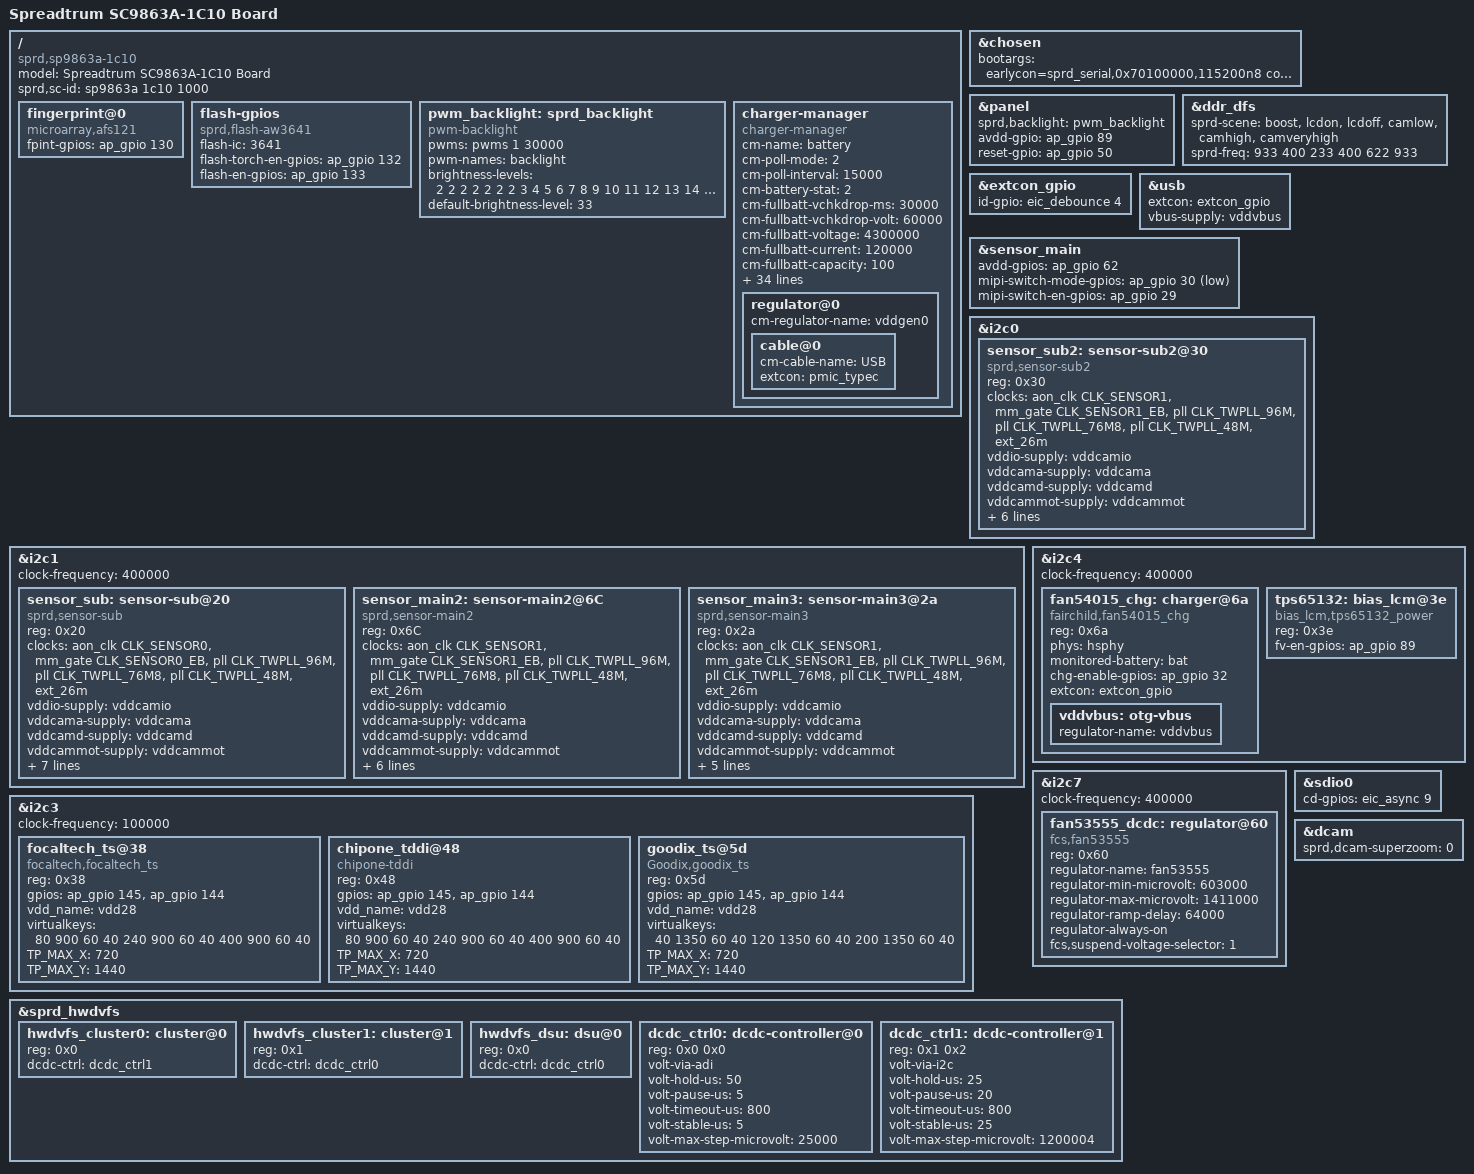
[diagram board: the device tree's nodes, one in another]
/dts-v1/;
/plugin/;

#include <dt-bindings/input/input.h>
#include <dt-bindings/gpio/gpio.h>
#include <dt-bindings/clock/sprd,sc9863a-clk.h>

/ {
	model = "Spreadtrum SC9863A-1C10 Board";
	compatible = "sprd,sp9863a-1c10", "sprd,sc9863a";
	sprd,sc-id = "sp9863a 1c10 1000";

	fragment {
		target-path = "/";
		__overlay__ {
			fingerprint@0 {
				compatible = "microarray,afs121";
				fpint-gpios = <&ap_gpio 130 0>;
			};

			flash-gpios {
				compatible = "sprd,flash-aw3641";
				flash-ic = <3641>;
				flash-torch-en-gpios = <&ap_gpio 132 0>;
				flash-en-gpios = <&ap_gpio 133 0>;
			};

			pwm_backlight: sprd_backlight {
				compatible = "pwm-backlight";
				pwms = <&pwms 1 30000>;
				pwm-names = "backlight";
				brightness-levels = <
								  2   2   2   2
					  2   2   2   3   4   5   6   7   8   9
					 10  11  12  13  14  15  16  17  18  19
					 20  21  22  23  24  25  26  27  28  29
					 30  31  32  33  34  35  36  37  38  39
					 40  41  42  43  44  45  46  47  48  49
					 50  51  52  53  54  55  56  57  58  59
					 60  61  62  63  64  65  66  67  68  69
					 70  71  72  73  74  75  76  77  78  79
					 80  81  82  83  84  85  86  87  88  89
					 90  91  92  93  94  95  96  97  98  99
					100 101 102 103 104 105 106 107 108 109
					110 111 112 113 114 115 116 117 118 119
					120 121 122 123 124 125 126 127 128 129
					130 131 132 133 134 135 136 137 138 139
					140 141 142 143 144 145 146 147 148 149
					150 151 152 153 154 155 156 157 158 159
					160 161 162 163 164 165 166 167 168 169
					170 171 172 173 174 175 176 177 178 179
					180 181 182 183 184 185 186 187 188 189
					190 191 192 193 194 195 196 197 198 199
					200 201 202 203 204 205 206 207 208 209
					210 211 212 213 214 215 216 217 218 219
					220 221 222 223 224 225 226 227 228 229
					230 231 232 233 234 235 236 237 238 239
					240 241 242 243 244 245 246 247 248 249
					250 251
				>;
				default-brightness-level = <33>;
			};

			charger-manager {
				compatible = "charger-manager";
				cm-name = "battery";
				cm-poll-mode = <2>;
				cm-poll-interval = <15000>;
				cm-battery-stat = <2>;

				cm-fullbatt-vchkdrop-ms = <30000>;
				cm-fullbatt-vchkdrop-volt = <60000>;
				cm-fullbatt-voltage = <4300000>;
				cm-fullbatt-current = <120000>;
				cm-fullbatt-capacity = <100>;

				cm-num-chargers = <1>;
				cm-chargers = "fan54015_charger";
				cm-fuel-gauge = "sc27xx-fgu";

				/* in deci centigrade */
				cm-battery-cold = <200>;
				cm-battery-cold-in-minus;
				cm-battery-hot = <800>;
				cm-battery-temp-diff = <100>;

				/* Allow charging for 6hr */
				cm-charging-max = <21600000>;
				/* recovery charging after stop charging 3hr */
				cm-discharging-max = <10800000>;

				/* the interval to feed charger watchdog */
				cm-wdt-interval = <60>;

				/* drop voltage in microVolts to allow shutdown */
				cm-shutdown-voltage = <3100000>;

				/* when 99% of the time is exceeded, it will be forced to 100% */
				cm-tickle-time-out = <1500>;

				/* how much time to allow capacity change */
				cm-one-cap-time = <30>;

				/* when the safe charging voltage is exceeded, stop charging */
				cm-charge-voltage-max = <6500000>;
				/* drop voltage in microVolts to restart charging */
				cm-charge-voltage-drop = <700000>;
				cm-dcp-jeita-temp-table = <1000 1030 0 4350000>,
					<1150 1180 700000 4350000>,
					<1450 1420 1150000 4350000>,
					<1600 1570 700000 4100000>;
				cm-sdp-jeita-temp-table = <1000 1030 0 4350000>,
					<1150 1180 500000 4350000>,
					<1450 1420 500000 4350000>,
					<1600 1570 500000 4100000>;
				cm-cdp-jeita-temp-table = <1000 1030 0 4350000>,
					<1150 1180 700000 4350000>,
					<1450 1420 1150000 4350000>,
					<1600 1570 700000 4100000>;
				cm-unknown-jeita-temp-table = <1000 1030 0 4350000>,
					<1150 1180 500000 4350000>,
					<1450 1420 500000 4350000>,
					<1600 1570 500000 4100000>;

				monitored-battery = <&bat>;
				cm-capacity-track;

				regulator@0 {
					cm-regulator-name = "vddgen0";
					cable@0 {
						cm-cable-name = "USB";
						extcon = <&pmic_typec>;
					};
				};
			};
		};
	};
};

&chosen {
	bootargs = "earlycon=sprd_serial,0x70100000,115200n8 console=ttyS1,115200n8 loglevel=1 init=/init root=/dev/ram0 rw androidboot.hardware=s9863a1c10 androidboot.dtbo_idx=0 printk.devkmsg=on androidboot.boot_devices=soc/soc:ap-ahb/20600000.sdio";
};

&panel {
	sprd,backlight = <&pwm_backlight>;
	avdd-gpio = <&ap_gpio 89 GPIO_ACTIVE_HIGH>;
	reset-gpio = <&ap_gpio 50 GPIO_ACTIVE_HIGH>;
};

&ddr_dfs {
	sprd-scene = "boost", "lcdon", "lcdoff", "camlow",
			"camhigh", "camveryhigh";
	sprd-freq = <933 400 233 400 622 933>;
};

&extcon_gpio {
	id-gpio = <&eic_debounce 4 GPIO_ACTIVE_HIGH>;
};

&usb {
	extcon = <&extcon_gpio>;
	vbus-supply = <&vddvbus>;
};

&sensor_main {
	avdd-gpios=<&ap_gpio 62 0>;
	mipi-switch-mode-gpios= <&ap_gpio 30 1>;
	mipi-switch-en-gpios= <&ap_gpio 29 0>;
};

&i2c0 {
	sensor_sub2: sensor-sub2@30 {
		compatible = "sprd,sensor-sub2";
		reg = <0x30>;
		clock-names = "clk_src","sensor_eb",
			"clk_96m","clk_76m8",
			"clk_48m","clk_26m";
		clocks = <&aon_clk CLK_SENSOR1>, <&mm_gate CLK_SENSOR1_EB>,
			<&pll CLK_TWPLL_96M>,<&pll CLK_TWPLL_76M8>,
			<&pll CLK_TWPLL_48M>,<&ext_26m>;
		vddio-supply = <&vddcamio>;
		vddcama-supply = <&vddcama>;
		vddcamd-supply = <&vddcamd>;
		vddcammot-supply = <&vddcammot>;
		sprd,phyid = <2>;
		csi = <&csi1>;
		iovdd-gpios=<&ap_gpio 15 0>;
		dvdd-gpios=<&ap_gpio 5 0>;
		reset-gpios = <&ap_gpio 16 0>;
		power-down-gpios = <&ap_gpio 57 0>;
	};
};

&i2c1 {
	status = "okay";
	clock-frequency = <400000>;

	sensor_sub: sensor-sub@20 {
		compatible = "sprd,sensor-sub";
		reg = <0x20>;
		clock-names = "clk_src","sensor_eb",
			"clk_96m","clk_76m8",
			"clk_48m","clk_26m";
		clocks = <&aon_clk CLK_SENSOR0>, <&mm_gate CLK_SENSOR0_EB>,
			<&pll CLK_TWPLL_96M>,<&pll CLK_TWPLL_76M8>,
			<&pll CLK_TWPLL_48M>,<&ext_26m>;
		vddio-supply = <&vddcamio>;
		vddcama-supply = <&vddcama>;
		vddcamd-supply = <&vddcamd>;
		vddcammot-supply = <&vddcammot>;
		sprd,phyid = <1>;
		csi = <&csi0>;
		avdd-gpios=<&ap_gpio 62 0>;
		mipi-switch-mode-gpios= <&ap_gpio 30 0>;
		mipi-switch-en-gpios= <&ap_gpio 29 0>;
		reset-gpios = <&ap_gpio 41 0>;
		power-down-gpios = <&ap_gpio 40 0>;
	};

	sensor_main2: sensor-main2@6C {
		compatible = "sprd,sensor-main2";
		reg = <0x6C>;
		clock-names = "clk_src","sensor_eb",
			"clk_96m","clk_76m8",
			"clk_48m","clk_26m";
		clocks = <&aon_clk CLK_SENSOR1>, <&mm_gate CLK_SENSOR1_EB>,
			<&pll CLK_TWPLL_96M>,<&pll CLK_TWPLL_76M8>,
			<&pll CLK_TWPLL_48M>,<&ext_26m>;
		vddio-supply = <&vddcamio>;
		vddcama-supply = <&vddcama>;
		vddcamd-supply = <&vddcamd>;
		vddcammot-supply = <&vddcammot>;
		sprd,phyid = <4>;
		csi = <&csi1>;
		iovdd-gpios=<&ap_gpio 15 0>;
		dvdd-gpios=<&ap_gpio 5 0>;
		reset-gpios = <&ap_gpio 56 0>;
		power-down-gpios = <&ap_gpio 59 0>;
	};

	sensor_main3: sensor-main3@2a {
		compatible = "sprd,sensor-main3";
		reg = <0x2a>;
		clock-names = "clk_src","sensor_eb",
			"clk_96m","clk_76m8",
			"clk_48m","clk_26m";
		clocks = <&aon_clk CLK_SENSOR1>, <&mm_gate CLK_SENSOR1_EB>,
			<&pll CLK_TWPLL_96M>,<&pll CLK_TWPLL_76M8>,
			<&pll CLK_TWPLL_48M>,<&ext_26m>;
		vddio-supply = <&vddcamio>;
		vddcama-supply = <&vddcama>;
		vddcamd-supply = <&vddcamd>;
		vddcammot-supply = <&vddcammot>;
		sprd,phyid = <3>;
		csi = <&csi1>;
		dvdd-gpios=<&ap_gpio 142 0>;
		reset-gpios = <&ap_gpio 45 0>;
		power-down-gpios = <&ap_gpio 47 0>;
	};
};

&i2c3 {
	status = "okay";
	clock-frequency = <100000>;
	focaltech_ts@38 {
		compatible = "focaltech,focaltech_ts";
		reg = <0x38>;
		gpios = <&ap_gpio 145 0
			&ap_gpio 144 0>;
		vdd_name = "vdd28";
		virtualkeys = <80 900 60 40
				240 900 60 40
				400 900 60 40>;
		TP_MAX_X = <720>;
		TP_MAX_Y = <1440>;
	};
	chipone_tddi@48 {
		compatible = "chipone-tddi";
		reg = <0x48>;
		gpios = <&ap_gpio 145 0
			&ap_gpio 144 0>;
		vdd_name = "vdd28";
		virtualkeys = <80 900 60 40
				240 900 60 40
				400 900 60 40>;
		TP_MAX_X = <720>;
		TP_MAX_Y = <1440>;
	};

	goodix_ts@5d {
		compatible = "Goodix,goodix_ts";
		reg = <0x5d>;
		gpios = <&ap_gpio 145 0
			&ap_gpio 144 0>;
		vdd_name = "vdd28";
		virtualkeys = <40 1350 60 40
			120 1350 60 40
			200 1350 60 40>;
		TP_MAX_X = <720>;
		TP_MAX_Y = <1440>;
	};
};

&i2c4 {
	status = "okay";
	clock-frequency = <400000>;

	fan54015_chg: charger@6a {
		compatible = "fairchild,fan54015_chg";
		reg = <0x6a>;
		phys = <&hsphy>;
		monitored-battery = <&bat>;
		chg-enable-gpios = <&ap_gpio 32 0>;
		extcon = <&extcon_gpio>;
		vddvbus:otg-vbus {
			regulator-name = "vddvbus";
		};
	};

	tps65132: bias_lcm@3e {/*WW6 just for fs170 lcm 5v*/
		compatible = "bias_lcm,tps65132_power";
		reg = <0x3e>;
		fv-en-gpios = <&ap_gpio 89 0>;
	};
};

&i2c7 {
	status = "okay";
	clock-frequency = <400000>;

	fan53555_dcdc: regulator@60 {
		compatible = "fcs,fan53555";
		reg = <0x60>;
		regulator-name = "fan53555";
		regulator-min-microvolt = <603000>;
		regulator-max-microvolt = <1411000>;
		regulator-ramp-delay = <64000>;
		regulator-always-on;
		fcs,suspend-voltage-selector = <1>;
	};
};

&sdio0 {
	cd-gpios = <&eic_async 9 0>;/*ww6 sd hot plut */
};

&dcam {
	status = "okay";
	sprd,dcam-superzoom = <0>;
};

&sprd_hwdvfs {
	hwdvfs_cluster0: cluster@0 {
		reg = <0x0>;
		dcdc-ctrl = <&dcdc_ctrl1>;
	};

	hwdvfs_cluster1: cluster@1 {
		reg = <0x1>;
		dcdc-ctrl = <&dcdc_ctrl0>;
	};

	hwdvfs_dsu: dsu@0 {
		reg = <0x0>;
		dcdc-ctrl = <&dcdc_ctrl0>;
	};

	dcdc_ctrl0: dcdc-controller@0 {
		reg = <0x0 0x0>;
		volt-via-adi;
		volt-hold-us = <50>;
		volt-pause-us = <5>;
		volt-timeout-us = <800>;
		volt-stable-us  = <5>;
		volt-max-step-microvolt = <25000>;
	};

	dcdc_ctrl1: dcdc-controller@1 {
		reg = <0x1 0x2>;
		volt-via-i2c;
		volt-hold-us = <25>;
		volt-pause-us = <20>;
		volt-timeout-us = <800>;
		volt-stable-us  = <25>;
		volt-max-step-microvolt = <1200004>;
	};
};

